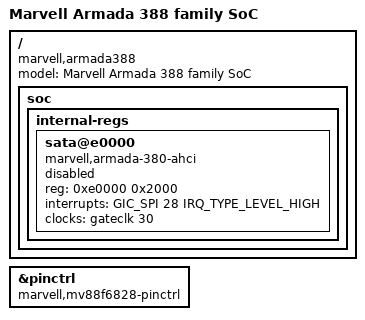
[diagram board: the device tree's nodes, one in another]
#include "armada-385.dtsi"
/ {
	model = "Marvell Armada 388 family SoC";
	compatible = "marvell,armada388", "marvell,armada385",
		"marvell,armada380";
	soc {
		internal-regs {
			sata@e0000 {
				compatible = "marvell,armada-380-ahci";
				reg = <0xe0000 0x2000>;
				interrupts = <GIC_SPI 28 IRQ_TYPE_LEVEL_HIGH>;
				clocks = <&gateclk 30>;
				status = "disabled";
			};
		};
	};
};
&pinctrl {
	compatible = "marvell,mv88f6828-pinctrl";
};
